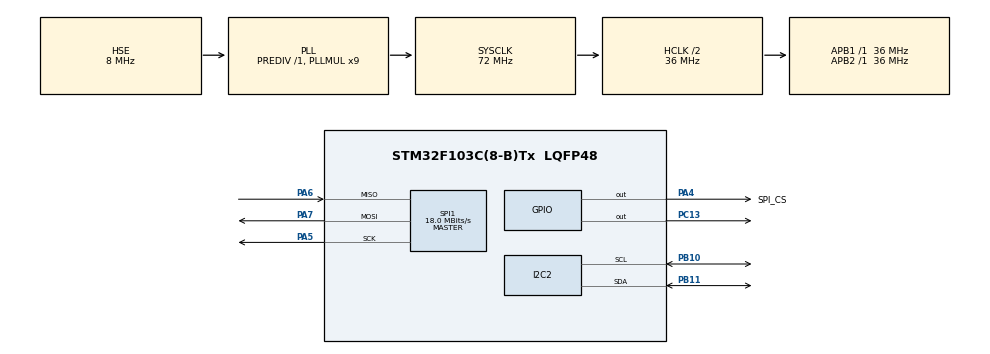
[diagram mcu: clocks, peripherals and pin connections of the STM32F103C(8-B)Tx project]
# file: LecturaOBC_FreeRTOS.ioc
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FREERTOS.INCLUDE_uxTaskGetStackHighWaterMark=1
FREERTOS.INCLUDE_vTaskDelayUntil=1
FREERTOS.Queues01=ColaLecturaOBC,1,uint32_t,0,Dynamic,NULL,NULL
FREERTOS.Tasks01=TareaLecturaOBC,0,256,StartLecturaOBC,Default,NULL,Dynamic,NULL,NULL;Consolidacion,0,256,StartConsolidacion,Default,NULL,Dynamic,NULL,NULL
Mcu.Family=STM32F1
Mcu.Name=STM32F103C(8-B)Tx
Mcu.Package=LQFP48
NVIC.PriorityGroup=NVIC_PRIORITYGROUP_4
NVIC.TIM1_UP_IRQn=true\:15\:0\:false\:false\:true\:false\:false\:true\:true
NVIC.TimeBase=TIM1_UP_IRQn
NVIC.TimeBaseIP=TIM1
PA13.Mode=Serial_Wire
PA13.Signal=SYS_JTMS-SWDIO
PA14.Mode=Serial_Wire
PA14.Signal=SYS_JTCK-SWCLK
PA4.GPIO_Label=SPI_CS
PA4.GPIO_Speed=GPIO_SPEED_FREQ_HIGH
PA4.PinState=GPIO_PIN_SET
PA4.Signal=GPIO_Output
PA5.Mode=Full_Duplex_Master
PA5.Signal=SPI1_SCK
PA6.Mode=Full_Duplex_Master
PA6.Signal=SPI1_MISO
PA7.Mode=Full_Duplex_Master
PA7.Signal=SPI1_MOSI
PB10.Mode=I2C
PB10.Signal=I2C2_SCL
PB11.Mode=I2C
PB11.Signal=I2C2_SDA
PC13-TAMPER-RTC.PinState=GPIO_PIN_SET
PC13-TAMPER-RTC.Signal=GPIO_Output
PD0-OSC_IN.Mode=HSE-External-Oscillator
PD0-OSC_IN.Signal=RCC_OSC_IN
PD1-OSC_OUT.Mode=HSE-External-Oscillator
PD1-OSC_OUT.Signal=RCC_OSC_OUT
ProjectManager.HeapSize=0x200
ProjectManager.StackSize=0x400
ProjectManager.TargetToolchain=STM32CubeIDE
RCC.AHBCLKDivider=RCC_SYSCLK_DIV2
RCC.AHBFreq_Value=36000000
RCC.APB1Freq_Value=36000000
RCC.APB1TimFreq_Value=36000000
RCC.APB2Freq_Value=36000000
RCC.APB2TimFreq_Value=36000000
RCC.HCLKFreq_Value=36000000
RCC.PLLMUL=RCC_PLL_MUL9
RCC.PLLSourceVirtual=RCC_PLLSOURCE_HSE
RCC.SYSCLKFreq_VALUE=72000000
RCC.SYSCLKSource=RCC_SYSCLKSOURCE_PLLCLK
RCC.USBFreq_Value=72000000
SPI1.CalculateBaudRate=18.0 MBits/s
SPI1.Direction=SPI_DIRECTION_2LINES
SPI1.Mode=SPI_MODE_MASTER
SPI1.VirtualType=VM_MASTER
VP_FREERTOS_VS_CMSIS_V1.Mode=CMSIS_V1
VP_SYS_VS_tim1.Mode=TIM1
board=custom

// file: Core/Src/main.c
/* USER CODE BEGIN Header */
/**
  ******************************************************************************
  * @file           : main.c
  * @brief          : Main program body
  ******************************************************************************
  * @attention
  *
  * Copyright (c) 2026 STMicroelectronics.
  * All rights reserved.
  *
  * This software is licensed under terms that can be found in the LICENSE file
  * in the root directory of this software component.
  * If no LICENSE file comes with this software, it is provided AS-IS.
  *
  ******************************************************************************
  */
/* USER CODE END Header */
#include "main.h"
#include "cmsis_os.h"
#include "i2c.h"
#include "spi.h"
#include "gpio.h"

void SystemClock_Config(void);
void MX_FREERTOS_Init(void);

int main(void)
{

  /* MCU Configuration--------------------------------------------------------*/

  /* Reset of all peripherals, Initializes the Flash interface and the Systick. */
  HAL_Init();

  /* Configure the system clock */
  SystemClock_Config();

  /* Initialize all configured peripherals */
  MX_GPIO_Init();
  MX_SPI1_Init();
  MX_I2C2_Init();

  /* Call init function for freertos objects (in cmsis_os2.c) */
  MX_FREERTOS_Init();

  /* Start scheduler */
  osKernelStart();

  /* We should never get here as control is now taken by the scheduler */

  /* Infinite loop */
  while (1)
  {

  }
}

void SystemClock_Config(void)
{
  RCC_OscInitTypeDef RCC_OscInitStruct = {0};
  RCC_ClkInitTypeDef RCC_ClkInitStruct = {0};

  /** Initializes the RCC Oscillators according to the specified parameters
  * in the RCC_OscInitTypeDef structure.
  */
  RCC_OscInitStruct.OscillatorType = RCC_OSCILLATORTYPE_HSE;
  RCC_OscInitStruct.HSEState = RCC_HSE_ON;
  RCC_OscInitStruct.HSEPredivValue = RCC_HSE_PREDIV_DIV1;
  RCC_OscInitStruct.HSIState = RCC_HSI_ON;
  RCC_OscInitStruct.PLL.PLLState = RCC_PLL_ON;
  RCC_OscInitStruct.PLL.PLLSource = RCC_PLLSOURCE_HSE;
  RCC_OscInitStruct.PLL.PLLMUL = RCC_PLL_MUL9;
  if (HAL_RCC_OscConfig(&RCC_OscInitStruct) != HAL_OK)
  {
    Error_Handler();
  }

  /** Initializes the CPU, AHB and APB buses clocks
  */
  RCC_ClkInitStruct.ClockType = RCC_CLOCKTYPE_HCLK|RCC_CLOCKTYPE_SYSCLK
                              |RCC_CLOCKTYPE_PCLK1|RCC_CLOCKTYPE_PCLK2;
  RCC_ClkInitStruct.SYSCLKSource = RCC_SYSCLKSOURCE_PLLCLK;
  RCC_ClkInitStruct.AHBCLKDivider = RCC_SYSCLK_DIV2;
  RCC_ClkInitStruct.APB1CLKDivider = RCC_HCLK_DIV1;
  RCC_ClkInitStruct.APB2CLKDivider = RCC_HCLK_DIV1;

  if (HAL_RCC_ClockConfig(&RCC_ClkInitStruct, FLASH_LATENCY_2) != HAL_OK)
  {
    Error_Handler();
  }
}

void HAL_TIM_PeriodElapsedCallback(TIM_HandleTypeDef *htim)
{
  if (htim->Instance == TIM1)
  {
    HAL_IncTick();
  }
}

void Error_Handler(void)
{
  __disable_irq();
  while (1)
  {
  }
}

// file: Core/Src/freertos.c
/* USER CODE BEGIN Header */
/**
  ******************************************************************************
  * File Name          : freertos.c
  * Description        : Code for freertos applications
  ******************************************************************************
  * @attention
  *
  * Copyright (c) 2026 STMicroelectronics.
  * All rights reserved.
  *
  * This software is licensed under terms that can be found in the LICENSE file
  * in the root directory of this software component.
  * If no LICENSE file comes with this software, it is provided AS-IS.
  *
  ******************************************************************************
  */
/* USER CODE END Header */

#include "FreeRTOS.h"
#include "task.h"
#include "main.h"
#include "cmsis_os.h"

/* USER CODE BEGIN Includes */
#include "telemetria_obc.h"
#include "consolidacion.h"
/* USER CODE END Includes */

osThreadId TareaLecturaOBCHandle;
osThreadId ConsolidacionHandle;
osMessageQId ColaLecturaOBCHandle;

void StartLecturaOBC(void const * argument);
void StartConsolidacion(void const * argument);

void MX_FREERTOS_Init(void); /* (MISRA C 2004 rule 8.1) */

/* GetIdleTaskMemory prototype (linked to static allocation support) */
void vApplicationGetIdleTaskMemory( StaticTask_t **ppxIdleTaskTCBBuffer, StackType_t **ppxIdleTaskStackBuffer, uint32_t *pulIdleTaskStackSize );

/* USER CODE BEGIN GET_IDLE_TASK_MEMORY */
static StaticTask_t xIdleTaskTCBBuffer;
static StackType_t xIdleStack[configMINIMAL_STACK_SIZE];

void vApplicationGetIdleTaskMemory( StaticTask_t **ppxIdleTaskTCBBuffer, StackType_t **ppxIdleTaskStackBuffer, uint32_t *pulIdleTaskStackSize )
{
  *ppxIdleTaskTCBBuffer = &xIdleTaskTCBBuffer;
  *ppxIdleTaskStackBuffer = &xIdleStack[0];
  *pulIdleTaskStackSize = configMINIMAL_STACK_SIZE;
  /* place for user code */
}
/* USER CODE END GET_IDLE_TASK_MEMORY */

void MX_FREERTOS_Init(void) {

  /* Create the queue(s) */
  /* definition and creation of ColaLecturaOBC */
  osMessageQDef(ColaLecturaOBC, 1, uint32_t);
  ColaLecturaOBCHandle = osMessageCreate(osMessageQ(ColaLecturaOBC), NULL);

  /* Create the thread(s) */
  /* definition and creation of TareaLecturaOBC */
  osThreadDef(TareaLecturaOBC, StartLecturaOBC, osPriorityNormal, 0, 256);
  TareaLecturaOBCHandle = osThreadCreate(osThread(TareaLecturaOBC), NULL);

  /* definition and creation of Consolidacion */
  osThreadDef(Consolidacion, StartConsolidacion, osPriorityNormal, 0, 256);
  ConsolidacionHandle = osThreadCreate(osThread(Consolidacion), NULL);

}

void StartLecturaOBC(void const * argument)
{
  /* USER CODE BEGIN StartLecturaOBC */
  /* Infinite loop */
  //for(;;)
  //{
  //  osDelay(1);
  //
	OBC_IniciarLectura((void*)argument);
  /* USER CODE END StartLecturaOBC */
}

void StartConsolidacion(void const * argument)
{
  /* USER CODE BEGIN StartConsolidacion */
  /* Infinite loop */
  //for(;;)
  //{
  //  osDelay(1);
  //}
	OBC_IniciarConsolidacion((void*)argument);
  /* USER CODE END StartConsolidacion */
}
